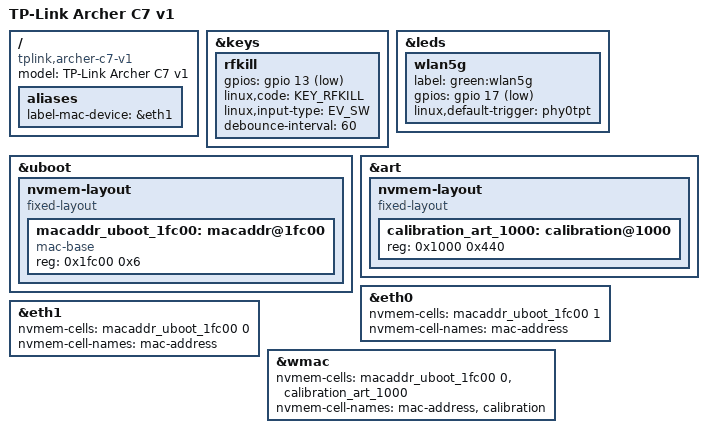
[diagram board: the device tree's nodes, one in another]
// SPDX-License-Identifier: GPL-2.0-or-later OR MIT

#include "qca9558_tplink_archer-c.dtsi"

/ {
	compatible = "tplink,archer-c7-v1", "qca,qca9558";
	model = "TP-Link Archer C7 v1";

	aliases {
		label-mac-device = &eth1;
	};
};

&keys {
	rfkill {
		gpios = <&gpio 13 GPIO_ACTIVE_LOW>;
		linux,code = <KEY_RFKILL>;
		linux,input-type = <EV_SW>;
		debounce-interval = <60>;
	};
};

&leds {
	wlan5g {
		label = "green:wlan5g";
		gpios = <&gpio 17 GPIO_ACTIVE_LOW>;
		linux,default-trigger = "phy0tpt";
	};
};

&uboot {
	nvmem-layout {
		compatible = "fixed-layout";
		#address-cells = <1>;
		#size-cells = <1>;

		macaddr_uboot_1fc00: macaddr@1fc00 {
			compatible = "mac-base";
			reg = <0x1fc00 0x6>;
			#nvmem-cell-cells = <1>;
		};
	};
};

&art {
	nvmem-layout {
		compatible = "fixed-layout";
		#address-cells = <1>;
		#size-cells = <1>;

		calibration_art_1000: calibration@1000 {
			reg = <0x1000 0x440>;
		};
	};
};

&eth0 {
	nvmem-cells = <&macaddr_uboot_1fc00 1>;
	nvmem-cell-names = "mac-address";
};

&eth1 {
	nvmem-cells = <&macaddr_uboot_1fc00 0>;
	nvmem-cell-names = "mac-address";
};

&wmac {
	nvmem-cells = <&macaddr_uboot_1fc00 0>, <&calibration_art_1000>;
	nvmem-cell-names = "mac-address", "calibration";
};
